VERSION ""

NS_ :

BS_:

BU_: SENSOR_CONTROL_UNIT VEHICLE_CONTROL_UNIT MOTOR_CONTROLLER EMUS_BMS U2C
VAL_TABLE_ SWITCH_TOGGLE 1 "TRUE/ON" 0 "FALSE/OFF" ;
VAL_TABLE_ MC_BUS_STATE 1 "CHARGED" 0 "DISCHARGED" ;
VAL_TABLE_ SET_INVERTER_DISCHARGE 1 "ENABLED" 0 "DISABLED" ;
VAL_TABLE_ SET_INVERTER_ENABLE 1 "ENABLED" 0 "DISABLED" ;
VAL_TABLE_ SET_MC_DIRECTION 1 "FORWARD" 0 "REVERSE" ;
VAL_TABLE_ DriveState 0 "DriveDisabled" ;

BO_ 3221225472 VECTOR__INDEPENDENT_SIG_MSG: 0 Vector__XXX
 SG_ New_Signal_655 : 0|8@1+ (1,0) [0|0] "" Vector__XXX
 SG_ Team_Signal_4 : 0|32@0- (1,0) [-2147483648|2147483647] "" Vector__XXX
 SG_ Team_Signal_3 : 0|32@0- (1,0) [-2147483648|2147483647] "" Vector__XXX
 SG_ Team_Signal_2 : 0|32@0- (1,0) [-2147483648|2147483647] "" Vector__XXX
 SG_ Team_Signal_1 : 0|32@0- (1,0) [-2147483648|2147483647] "" Vector__XXX

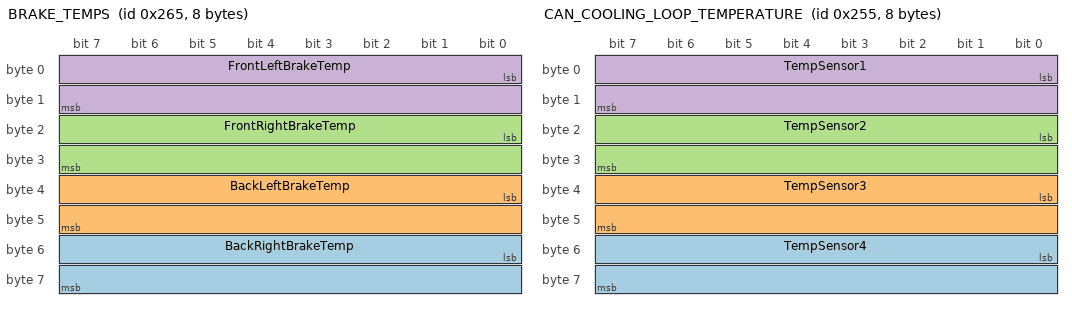
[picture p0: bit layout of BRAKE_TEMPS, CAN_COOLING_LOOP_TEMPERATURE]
BO_ 613 BRAKE_TEMPS: 8 SENSOR_CONTROL_UNIT
 SG_ BackRightBrakeTemp : 48|16@1- (0.01,0) [-327.68|327.67] "degC" Vector__XXX
 SG_ BackLeftBrakeTemp : 32|16@1- (0.01,0) [-327.68|327.67] "degC" Vector__XXX
 SG_ FrontRightBrakeTemp : 16|16@1- (0.01,0) [-327.68|327.67] "degC" Vector__XXX
 SG_ FrontLeftBrakeTemp : 0|16@1- (0.01,0) [-327.68|327.67] "degC" Vector__XXX

BO_ 599 TWO_FOOT_RULE: 8 SENSOR_CONTROL_UNIT
 SG_ HTL_CH_ID_TWO_FOOT_RULE : 0|8@1+ (1,0) [0|1] "" Vector__XXX

BO_ 585 HTL_CH_ID_WARNING_0: 8 SENSOR_CONTROL_UNIT
 SG_ HTL_CH_ID_WARNING_0_BYTE_0 : 0|8@1+ (1,0) [0|255] "" Vector__XXX
 SG_ HTL_CH_ID_WARNING_0_BYTE_1 : 0|8@1+ (1,0) [0|255] "" Vector__XXX
 SG_ HTL_CH_ID_WARNING_0_BYTE_2 : 0|8@1+ (1,0) [0|255] "" Vector__XXX
 SG_ HTL_CH_ID_WARNING_0_BYTE_3 : 0|8@1+ (1,0) [0|255] "" Vector__XXX
 SG_ HTL_CH_ID_WARNING_0_BYTE_4 : 0|8@1+ (1,0) [0|255] "" Vector__XXX
 SG_ HTL_CH_ID_WARNING_0_BYTE_5 : 0|8@1+ (1,0) [0|255] "" Vector__XXX
 SG_ HTL_CH_ID_WARNING_0_BYTE_6 : 0|8@1+ (1,0) [0|255] "" Vector__XXX
 SG_ HTL_CH_ID_WARNING_0_BYTE_7 : 0|8@1+ (1,0) [0|255] "" Vector__XXX

BO_ 592 HTL_CH_ID_WARNING_1: 8 SENSOR_CONTROL_UNIT
 SG_ HTL_CH_ID_WARNING_1_BYTE_0 : 0|8@1+ (1,0) [0|255] "" Vector__XXX
 SG_ HTL_CH_ID_WARNING_1_BYTE_1 : 0|8@1+ (1,0) [0|255] "" Vector__XXX
 SG_ HTL_CH_ID_WARNING_1_BYTE_2 : 0|8@1+ (1,0) [0|255] "" Vector__XXX
 SG_ HTL_CH_ID_WARNING_1_BYTE_3 : 0|8@1+ (1,0) [0|255] "" Vector__XXX
 SG_ HTL_CH_ID_WARNING_1_BYTE_4 : 0|8@1+ (1,0) [0|255] "" Vector__XXX
 SG_ HTL_CH_ID_WARNING_1_BYTE_5 : 0|8@1+ (1,0) [0|255] "" Vector__XXX
 SG_ HTL_CH_ID_WARNING_1_BYTE_6 : 0|8@1+ (1,0) [0|255] "" Vector__XXX
 SG_ HTL_CH_ID_WARNING_1_BYTE_7 : 0|8@1+ (1,0) [0|255] "" Vector__XXX

BO_ 544 HTL_CH_ID_APPS_TO_TORQUE_REQUEST: 8 SENSOR_CONTROL_UNIT
 SG_ HTL_CH_ID_APPS_TO_TORQUE_REQUEST : 0|16@1+ (0.1,0) [0|2400] "Nm" Vector__XXX

BO_ 537 HTL_CH_ID_BRAKE_PRESSED: 8 SENSOR_CONTROL_UNIT
 SG_ HTL_CH_ID_BRAKE_PRESSED : 0|8@1+ (1,0) [0|1] "" Vector__XXX

BO_ 536 HTL_CH_ID_APPS_PRESSED: 8 SENSOR_CONTROL_UNIT
 SG_ HTL_CH_ID_APPS_PRESSED : 0|8@1+ (1,0) [0|1] "" Vector__XXX

BO_ 535 HTL_CH_ID_SAFETY_LOOP_STATUS: 8 SENSOR_CONTROL_UNIT
 SG_ HTL_CH_ID_SAFETY_LOOP_STATUS : 0|8@1+ (1,0) [0|1] "" Vector__XXX

BO_ 598 CAN_FLOW_METER: 2 SENSOR_CONTROL_UNIT
 SG_ FlowRate : 0|16@1+ (0.01,0) [0|655.35] "L/s" Vector__XXX

BO_ 597 CAN_COOLING_LOOP_TEMPERATURE: 8 SENSOR_CONTROL_UNIT
 SG_ TempSensor4 : 48|16@1- (0.01,0) [-327.68|327.67] "degC" Vector__XXX
 SG_ TempSensor3 : 32|16@1- (0.01,0) [-327.68|327.67] "degC" Vector__XXX
 SG_ TempSensor2 : 16|16@1- (0.01,0) [-327.68|327.67] "degC" Vector__XXX
 SG_ TempSensor1 : 0|16@1- (0.01,0) [-327.68|327.67] "degC" Vector__XXX

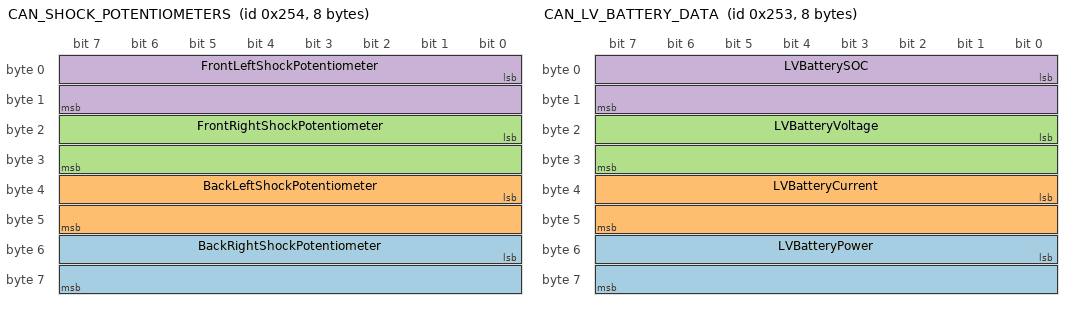
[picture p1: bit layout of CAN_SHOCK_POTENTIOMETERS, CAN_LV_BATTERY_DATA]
BO_ 596 CAN_SHOCK_POTENTIOMETERS: 8 SENSOR_CONTROL_UNIT
 SG_ BackRightShockPotentiometer : 48|16@1+ (0.01,0) [0|655.35] "mm" Vector__XXX
 SG_ BackLeftShockPotentiometer : 32|16@1+ (0.01,0) [0|655.35] "mm" Vector__XXX
 SG_ FrontRightShockPotentiometer : 16|16@1+ (0.01,0) [0|655.35] "mm" Vector__XXX
 SG_ FrontLeftShockPotentiometer : 0|16@1+ (0.01,0) [0|655.35] "mm" Vector__XXX

BO_ 595 CAN_LV_BATTERY_DATA: 8 SENSOR_CONTROL_UNIT
 SG_ LVBatteryPower : 48|16@1+ (0.01,0) [0|655.35] "W" Vector__XXX
 SG_ LVBatteryCurrent : 32|16@1- (0.01,0) [-327.68|327.67] "A" Vector__XXX
 SG_ LVBatteryVoltage : 16|16@1- (0.01,0) [-327.68|327.67] "V" Vector__XXX
 SG_ LVBatterySOC : 0|16@1+ (0.01,0) [0|655.35] "%" Vector__XXX

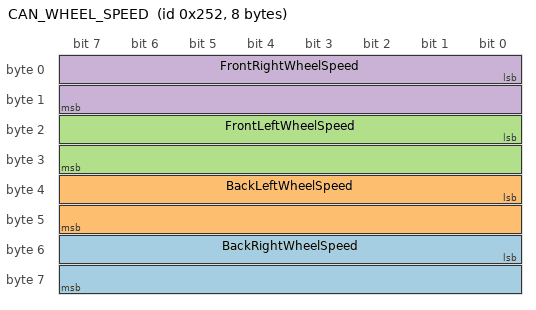
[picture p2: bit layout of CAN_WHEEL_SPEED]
BO_ 594 CAN_WHEEL_SPEED: 8 SENSOR_CONTROL_UNIT
 SG_ BackRightWheelSpeed : 48|16@1- (0.01,0) [-327.68|327.67] "kph" Vector__XXX
 SG_ BackLeftWheelSpeed : 32|16@1- (0.01,0) [-327.68|327.67] "kph" Vector__XXX
 SG_ FrontLeftWheelSpeed : 16|16@1- (0.01,0) [-327.68|327.67] "kph" Vector__XXX
 SG_ FrontRightWheelSpeed : 0|16@1- (0.01,0) [-327.68|327.67] "kph" Vector__XXX

BO_ 593 CAN_VEHICLE_SPEED: 2 SENSOR_CONTROL_UNIT
 SG_ Vehicle_Speed : 0|16@1- (0.01,0) [-327.68|327.67] "kph" Vector__XXX

CM_ BU_ VEHICLE_CONTROL_UNIT "The system vehicle control unit";
CM_ BU_ MOTOR_CONTROLLER "The Cascadia Motion inverter";
CM_ BU_ EMUS_BMS "BMS Master";
CM_ BU_ U2C "Delphi DC/DC Converter";
CM_ BO_ 3221225472 "This is a message for not used signals, created by Vector CANdb++ DBC OLE DB Provider.";
BA_DEF_  "BusType" STRING ;
BA_DEF_DEF_  "BusType" "CAN";
